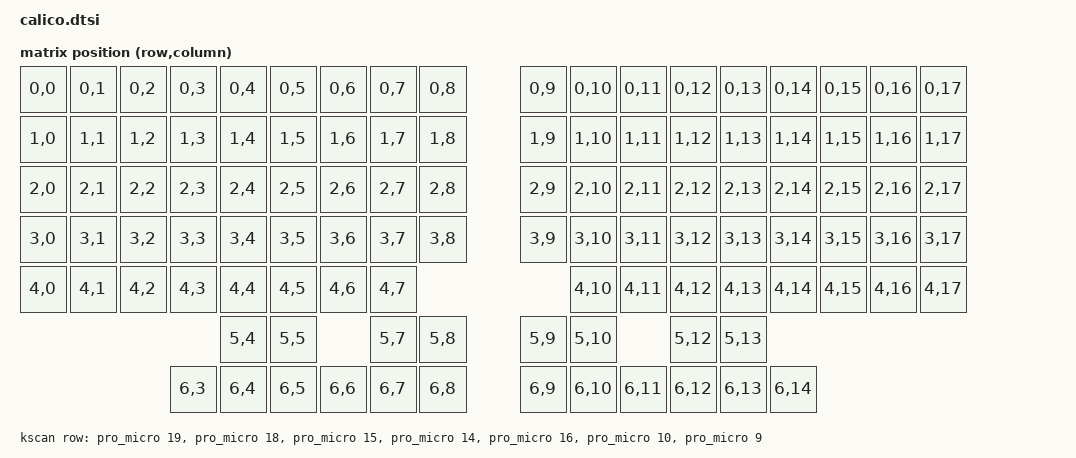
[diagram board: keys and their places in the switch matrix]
// This file was generated from a template. Edit it to match your keyboard.
// See https://zmk.dev/docs/development/hardware-integration/new-shield for more
// instructions.

#include <dt-bindings/zmk/matrix_transform.h>

// #include "calico-layouts.dtsi"

/ {
    chosen {
        zmk,physical-layout = &default_layout;
    };

    default_layout: default_layout {
        compatible = "zmk,physical-layout";
        display-name = "calico-keyboard";
        transform = <&default_transform>;
        kscan = <&kscan>;
    };

    kscan: kscan {
        // If the hardware does not use a switch matrix, change this to the
        // appropriate driver and update the properties below to match.
        // See https://zmk.dev/docs/config/kscan for supported key scan drivers.
        compatible = "zmk,kscan-gpio-matrix";
        // Set this to "col2row" or "row2col" to match the hardware. If using
        // "row2col", change the col-gpios in the _left.overlay and _right.overlay
        // files to (GPIO_ACTIVE_HIGH | GPIO_PULL_DOWN) and the row-gpios here to
        // GPIO_ACTIVE_HIGH.
        diode-direction = "col2row";
        wakeup-source;

        // Replace these comments with the GPIO pins in the matrix.
        // See https://zmk.dev/docs/development/hardware-integration/new-shield#shield-overlays
        
        
        row-gpios
            = <&pro_micro 19 (GPIO_ACTIVE_HIGH | GPIO_PULL_DOWN)>
            , <&pro_micro 18 (GPIO_ACTIVE_HIGH | GPIO_PULL_DOWN)>
            , <&pro_micro 15 (GPIO_ACTIVE_HIGH | GPIO_PULL_DOWN)>
            , <&pro_micro 14 (GPIO_ACTIVE_HIGH | GPIO_PULL_DOWN)>
            , <&pro_micro 16 (GPIO_ACTIVE_HIGH | GPIO_PULL_DOWN)>
            , <&pro_micro 10 (GPIO_ACTIVE_HIGH | GPIO_PULL_DOWN)>
            , <&pro_micro 9 (GPIO_ACTIVE_HIGH | GPIO_PULL_DOWN)>
            ;
    };

    default_transform: default_transform {
        // See https://zmk.dev/docs/development/hardware-integration/new-shield#matrix-transform
        // for how to configure this
        compatible = "zmk,matrix-transform";
        columns = <18>;
        rows = <7>;

        map = <
            // Left side                                                                       Right side
            RC(0,0) RC(0,1) RC(0,2) RC(0,3) RC(0,4) RC(0,5) RC(0,6) RC(0,7) RC(0,8)         RC(0,9) RC(0,10) RC(0,11) RC(0,12) RC(0,13) RC(0,14) RC(0,15) RC(0,16) RC(0,17) 
            RC(1,0) RC(1,1) RC(1,2) RC(1,3) RC(1,4) RC(1,5) RC(1,6) RC(1,7) RC(1,8)         RC(1,9) RC(1,10) RC(1,11) RC(1,12) RC(1,13) RC(1,14) RC(1,15) RC(1,16) RC(1,17) 
            RC(2,0) RC(2,1) RC(2,2) RC(2,3) RC(2,4) RC(2,5) RC(2,6) RC(2,7) RC(2,8)         RC(2,9) RC(2,10) RC(2,11) RC(2,12) RC(2,13) RC(2,14) RC(2,15) RC(2,16) RC(2,17) 
            RC(3,0) RC(3,1) RC(3,2) RC(3,3) RC(3,4) RC(3,5) RC(3,6) RC(3,7) RC(3,8)         RC(3,9) RC(3,10) RC(3,11) RC(3,12) RC(3,13) RC(3,14) RC(3,15) RC(3,16) RC(3,17) 
            RC(4,0) RC(4,1) RC(4,2) RC(4,3) RC(4,4) RC(4,5) RC(4,6) RC(4,7)                         RC(4,10) RC(4,11) RC(4,12) RC(4,13) RC(4,14) RC(4,15) RC(4,16) RC(4,17) 
                                            RC(5,4) RC(5,5)         RC(5,7) RC(5,8)         RC(5,9) RC(5,10)          RC(5,12) RC(5,13) 
                                    RC(6,3) RC(6,4) RC(6,5) RC(6,6) RC(6,7) RC(6,8)         RC(6,9) RC(6,10) RC(6,11) RC(6,12) RC(6,13) RC(6,14)
        >;
    };
};
